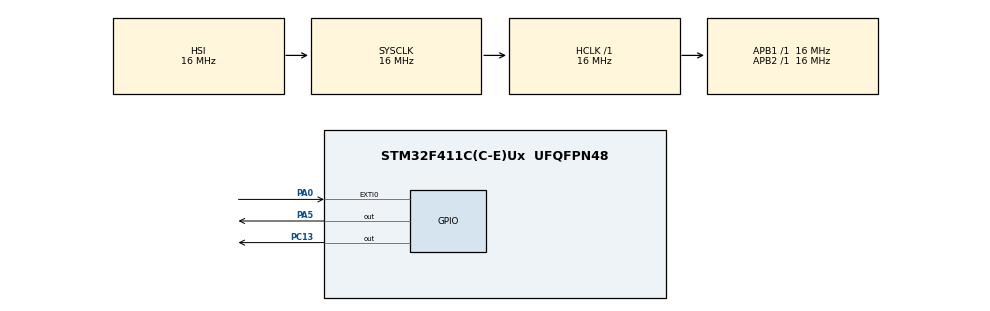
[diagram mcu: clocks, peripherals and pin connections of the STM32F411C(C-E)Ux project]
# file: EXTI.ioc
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Mcu.Family=STM32F4
Mcu.Name=STM32F411C(C-E)Ux
Mcu.Package=UFQFPN48
NVIC.EXTI0_IRQn=true\:0\:0\:false\:false\:true\:true\:true\:true
NVIC.PriorityGroup=NVIC_PRIORITYGROUP_4
PA0-WKUP.GPIO_PuPd=GPIO_PULLUP
PA0-WKUP.Signal=GPXTI0
PA5.Signal=GPIO_Output
PC13-ANTI_TAMP.Signal=GPIO_Output
ProjectManager.HeapSize=0x200
ProjectManager.StackSize=0x400
ProjectManager.TargetToolchain=STM32CubeIDE
RCC.AHBFreq_Value=16000000
RCC.APB1Freq_Value=16000000
RCC.APB2Freq_Value=16000000
RCC.CortexFreq_Value=16000000
RCC.HSE_VALUE=25000000
RCC.HSI_VALUE=16000000
RCC.LSE_VALUE=32768
RCC.SYSCLKFreq_VALUE=16000000
RCC.VCOOutputFreq_Value=192000000
board=custom

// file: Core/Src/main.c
/* USER CODE BEGIN Header */
/**
  ******************************************************************************
  * @file           : main.c
  * @brief          : Main program body
  ******************************************************************************
  * @attention
  *
  * Copyright (c) 2026 STMicroelectronics.
  * All rights reserved.
  *
  * This software is licensed under terms that can be found in the LICENSE file
  * in the root directory of this software component.
  * If no LICENSE file comes with this software, it is provided AS-IS.
  *
  ******************************************************************************
  */
/* USER CODE END Header */
#include "main.h"

/* USER CODE BEGIN Includes */
#define RCC_AHBIENR   0x40023800 + 0x30
#define RCC_APB2ENR   0x40023800 + 0x44
#define GPIOA_MODER   0x40020000 + 0x00
#define GPIOC_MODER   0x40020800 + 0x00
#define SYSCFG_ENBR   0x40013800 + 0x08
#define GPIOA_BSRR    0x40020000 + 0x18
#define GPIOA_ODR     0x40020000 + 0x14
#define GPIOA_PUPDR   0x40020000 + 0x0C
#define EXTI_IMR      0x40013C00 + 0x00
#define EXTI_FTSR     0x40013C00 + 0x0C
#define EXTI_PR       0x40013C00 + 0x14
#define GPIOC_ODR     0x40020800 + 0x14

/* USER CODE END Includes */

/* USER CODE BEGIN PD */
volatile int stop_main = 0;
/* USER CODE END PD */

void SystemClock_Config(void);
static void MX_GPIO_Init(void);

int main(void)
{

  /* USER CODE BEGIN 1 */
  uint32_t *p1 = (uint32_t*)RCC_AHBIENR;
  *p1|=(1<<0);   //GPIOA CLOCK ENABLE FOR PA5
  *p1|=(1<<2);   //GPIOC CLOCK ENABLE FOR PC13
  uint32_t *p7 = (uint32_t*)RCC_APB2ENR;
  *p7 |= (1 << 14);
  uint32_t *p2 = (uint32_t*)GPIOA_MODER;
  *p2 &= ~(3<<(5*2));
  *p2 |= (1<<(5*2));
  *p2 &= ~(3<<0);
  uint32_t *p3 = (uint32_t*)GPIOC_MODER;
  *p3 &= ~(3<<26);
  *p3 |= (1<<26);
  uint32_t *p4 = (uint32_t*)SYSCFG_ENBR;
  *p4 &= ~(0xF<<0);
  //uint32_t *p5 = (uint32_t*)GPIOA_ODR;
  uint32_t *p6 = (uint32_t*)GPIOA_PUPDR;
  *p6 &= ~(3<<0);
  *p6 |= (1<<0); // PULLUP FOR EXTI
  uint32_t *p8 = (uint32_t*)EXTI_IMR;
  *p8 |= (1<<0);
  uint32_t *p9 = (uint32_t*)EXTI_FTSR;
  *p9 |= (1<<0);

  uint32_t *p10 = (uint32_t*)GPIOC_ODR;
  ///uint32_t *p11 = (uint32_t*)EXTI_PR;

  /* USER CODE END 1 */

  /* MCU Configuration--------------------------------------------------------*/

  /* Reset of all peripherals, Initializes the Flash interface and the Systick. */
  HAL_Init();

  /* Configure the system clock */
  SystemClock_Config();

  /* Initialize all configured peripherals */
  MX_GPIO_Init();
  NVIC_EnableIRQ(EXTI0_IRQn);
  /* Infinite loop */
  /* USER CODE BEGIN WHILE */
  while(1)
  {
      if(stop_main == 0)
      {
          *p10 |= (1<<13);
          HAL_Delay(500);
          *p10 &= ~(1<<13);
          HAL_Delay(500);
      }
  }
  /* USER CODE END 3 */
}

void SystemClock_Config(void)
{
  RCC_OscInitTypeDef RCC_OscInitStruct = {0};
  RCC_ClkInitTypeDef RCC_ClkInitStruct = {0};

  /** Configure the main internal regulator output voltage
  */
  __HAL_RCC_PWR_CLK_ENABLE();
  __HAL_PWR_VOLTAGESCALING_CONFIG(PWR_REGULATOR_VOLTAGE_SCALE1);

  /** Initializes the RCC Oscillators according to the specified parameters
  * in the RCC_OscInitTypeDef structure.
  */
  RCC_OscInitStruct.OscillatorType = RCC_OSCILLATORTYPE_HSI;
  RCC_OscInitStruct.HSIState = RCC_HSI_ON;
  RCC_OscInitStruct.HSICalibrationValue = RCC_HSICALIBRATION_DEFAULT;
  RCC_OscInitStruct.PLL.PLLState = RCC_PLL_NONE;
  if (HAL_RCC_OscConfig(&RCC_OscInitStruct) != HAL_OK)
  {
    Error_Handler();
  }

  /** Initializes the CPU, AHB and APB buses clocks
  */
  RCC_ClkInitStruct.ClockType = RCC_CLOCKTYPE_HCLK|RCC_CLOCKTYPE_SYSCLK
                              |RCC_CLOCKTYPE_PCLK1|RCC_CLOCKTYPE_PCLK2;
  RCC_ClkInitStruct.SYSCLKSource = RCC_SYSCLKSOURCE_HSI;
  RCC_ClkInitStruct.AHBCLKDivider = RCC_SYSCLK_DIV1;
  RCC_ClkInitStruct.APB1CLKDivider = RCC_HCLK_DIV1;
  RCC_ClkInitStruct.APB2CLKDivider = RCC_HCLK_DIV1;

  if (HAL_RCC_ClockConfig(&RCC_ClkInitStruct, FLASH_LATENCY_0) != HAL_OK)
  {
    Error_Handler();
  }
}

static void MX_GPIO_Init(void)
{
  GPIO_InitTypeDef GPIO_InitStruct = {0};

  /* GPIO Ports Clock Enable */
  __HAL_RCC_GPIOC_CLK_ENABLE();
  __HAL_RCC_GPIOA_CLK_ENABLE();

  /*Configure GPIO pin Output Level */
  HAL_GPIO_WritePin(GPIOC, GPIO_PIN_13, GPIO_PIN_RESET);

  /*Configure GPIO pin Output Level */
  HAL_GPIO_WritePin(GPIOA, GPIO_PIN_5, GPIO_PIN_RESET);

  /*Configure GPIO pin : PC13 */
  GPIO_InitStruct.Pin = GPIO_PIN_13;
  GPIO_InitStruct.Mode = GPIO_MODE_OUTPUT_PP;
  GPIO_InitStruct.Pull = GPIO_NOPULL;
  GPIO_InitStruct.Speed = GPIO_SPEED_FREQ_LOW;
  HAL_GPIO_Init(GPIOC, &GPIO_InitStruct);

  /*Configure GPIO pin : PA0 */
  GPIO_InitStruct.Pin = GPIO_PIN_0;
  GPIO_InitStruct.Mode = GPIO_MODE_IT_RISING;
  GPIO_InitStruct.Pull = GPIO_PULLUP;
  HAL_GPIO_Init(GPIOA, &GPIO_InitStruct);

  /*Configure GPIO pin : PA5 */
  GPIO_InitStruct.Pin = GPIO_PIN_5;
  GPIO_InitStruct.Mode = GPIO_MODE_OUTPUT_PP;
  GPIO_InitStruct.Pull = GPIO_NOPULL;
  GPIO_InitStruct.Speed = GPIO_SPEED_FREQ_LOW;
  HAL_GPIO_Init(GPIOA, &GPIO_InitStruct);

  /* EXTI interrupt init*/
  HAL_NVIC_SetPriority(EXTI0_IRQn, 0, 0);
  HAL_NVIC_EnableIRQ(EXTI0_IRQn);

}

void Error_Handler(void)
{
  __disable_irq();
  while (1)
  {
  }
}
